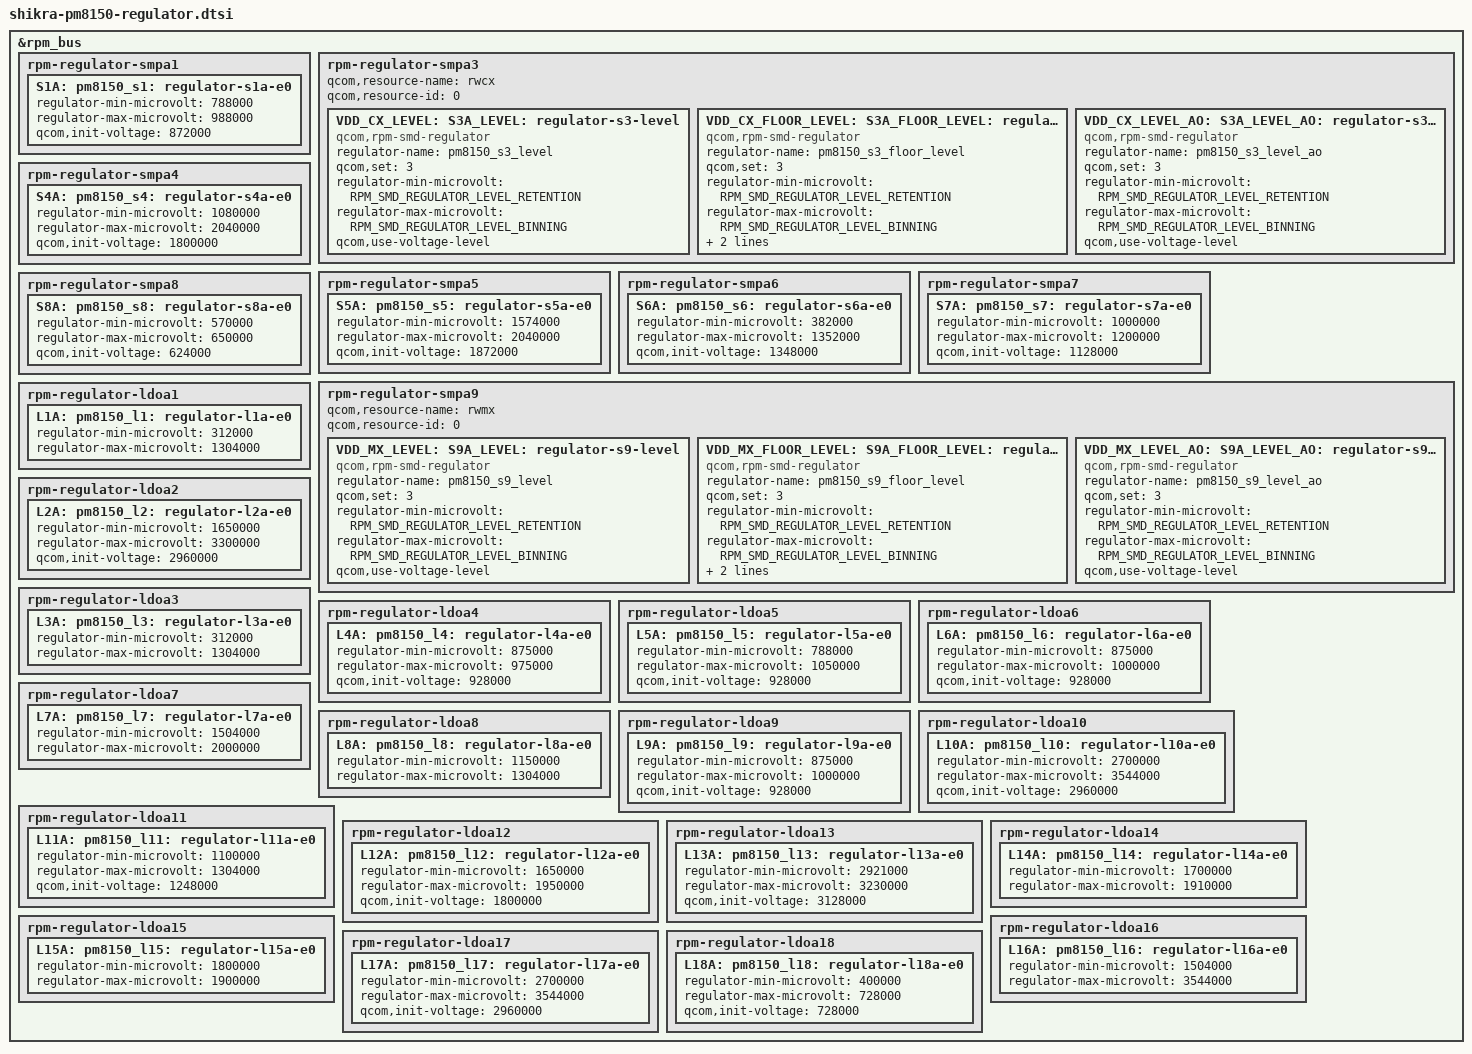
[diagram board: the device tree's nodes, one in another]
// SPDX-License-Identifier: BSD-3-Clause
/*
 * Copyright (c) Qualcomm Technologies, Inc. and/or its subsidiaries.
 */

#include <dt-bindings/regulator/qcom,rpm-smd-regulator.h>
#include "pm8150-rpm-regulator.dtsi"

&rpm_bus {
	rpm-regulator-smpa1 {
		status = "okay";
		S1A: pm8150_s1: regulator-s1a-e0 {
			regulator-min-microvolt = <788000>;
			regulator-max-microvolt = <988000>;
			qcom,init-voltage = <872000>;
			status = "okay";
		};
	};

	rpm-regulator-smpa3 {
		status = "okay";
		qcom,resource-name = "rwcx";
		qcom,resource-id = <0>;

		VDD_CX_LEVEL:
		S3A_LEVEL: pm8150_s3_level: regulator-s3-level {
			compatible = "qcom,rpm-smd-regulator";
			regulator-name = "pm8150_s3_level";
			qcom,set = <3>;
			regulator-min-microvolt =
			<RPM_SMD_REGULATOR_LEVEL_RETENTION>;
			regulator-max-microvolt =
			<RPM_SMD_REGULATOR_LEVEL_BINNING>;
			qcom,use-voltage-level;
		};

		VDD_CX_FLOOR_LEVEL:
		S3A_FLOOR_LEVEL:
		pm8150_s3_floor_level: regulator-s3-floor-level {
			compatible = "qcom,rpm-smd-regulator";
			regulator-name = "pm8150_s3_floor_level";
			qcom,set = <3>;
			regulator-min-microvolt =
			<RPM_SMD_REGULATOR_LEVEL_RETENTION>;
			regulator-max-microvolt =
			<RPM_SMD_REGULATOR_LEVEL_BINNING>;
			qcom,use-voltage-floor-level;
			qcom,always-send-voltage;
		};

		VDD_CX_LEVEL_AO:
		S3A_LEVEL_AO: pm8150_s3_level_ao: regulator-s3-level-ao {
			compatible = "qcom,rpm-smd-regulator";
			regulator-name = "pm8150_s3_level_ao";
			qcom,set = <3>;
			regulator-min-microvolt =
			<RPM_SMD_REGULATOR_LEVEL_RETENTION>;
			regulator-max-microvolt =
			<RPM_SMD_REGULATOR_LEVEL_BINNING>;
			qcom,use-voltage-level;
		};
	};

	rpm-regulator-smpa4 {
		status = "okay";
		S4A: pm8150_s4: regulator-s4a-e0 {
			regulator-min-microvolt = <1080000>;
			regulator-max-microvolt = <2040000>;
			qcom,init-voltage = <1800000>;
			status = "okay";
		};
	};

	rpm-regulator-smpa5 {
		status = "okay";
		S5A: pm8150_s5: regulator-s5a-e0 {
			regulator-min-microvolt = <1574000>;
			regulator-max-microvolt = <2040000>;
			qcom,init-voltage = <1872000>;
			status = "okay";
		};
	};

	rpm-regulator-smpa6 {
		status = "okay";
		S6A: pm8150_s6: regulator-s6a-e0 {
			regulator-min-microvolt = <382000>;
			regulator-max-microvolt = <1352000>;
			qcom,init-voltage = <1348000>;
			status = "okay";
		};
	};

	rpm-regulator-smpa7 {
		status = "okay";
		S7A: pm8150_s7: regulator-s7a-e0 {
			regulator-min-microvolt = <1000000>;
			regulator-max-microvolt = <1200000>;
			qcom,init-voltage = <1128000>;
			status = "okay";
		};
	};

	rpm-regulator-smpa8 {
		status = "okay";
		S8A: pm8150_s8: regulator-s8a-e0 {
			regulator-min-microvolt = <570000>;
			regulator-max-microvolt = <650000>;
			qcom,init-voltage = <624000>;
			status = "okay";
		};
	};

	/* PM8150 S9A - VDD_MX supply */
	rpm-regulator-smpa9 {
		status = "okay";
		qcom,resource-name = "rwmx";
		qcom,resource-id = <0>;

		VDD_MX_LEVEL:
		S9A_LEVEL: pm8150_s9_level: regulator-s9-level {
			compatible = "qcom,rpm-smd-regulator";
			regulator-name = "pm8150_s9_level";
			qcom,set = <3>;
			regulator-min-microvolt =
			<RPM_SMD_REGULATOR_LEVEL_RETENTION>;
			regulator-max-microvolt =
			<RPM_SMD_REGULATOR_LEVEL_BINNING>;
			qcom,use-voltage-level;
		};

		VDD_MX_FLOOR_LEVEL:
		S9A_FLOOR_LEVEL:
		pm8150_s9_floor_level: regulator-s9-floor-level {
			compatible = "qcom,rpm-smd-regulator";
			regulator-name = "pm8150_s9_floor_level";
			qcom,set = <3>;
			regulator-min-microvolt =
			<RPM_SMD_REGULATOR_LEVEL_RETENTION>;
			regulator-max-microvolt =
			<RPM_SMD_REGULATOR_LEVEL_BINNING>;
			qcom,use-voltage-floor-level;
			qcom,always-send-voltage;
		};

		VDD_MX_LEVEL_AO:
		S9A_LEVEL_AO: pm8150_s9_level_ao: regulator-s9-level-ao {
			compatible = "qcom,rpm-smd-regulator";
			regulator-name = "pm8150_s9_level_ao";
			qcom,set = <3>;
			regulator-min-microvolt =
			<RPM_SMD_REGULATOR_LEVEL_RETENTION>;
			regulator-max-microvolt =
			<RPM_SMD_REGULATOR_LEVEL_BINNING>;
			qcom,use-voltage-level;
		};
	};

	rpm-regulator-ldoa1 {
		status = "okay";
		L1A: pm8150_l1: regulator-l1a-e0 {
			regulator-min-microvolt = <312000>;
			regulator-max-microvolt = <1304000>;
			status = "okay";
		};
	};

	rpm-regulator-ldoa2 {
		status = "okay";
		L2A: pm8150_l2: regulator-l2a-e0 {
			regulator-min-microvolt = <1650000>;
			regulator-max-microvolt = <3300000>;
			qcom,init-voltage = <2960000>;
			status = "okay";
		};
	};

	rpm-regulator-ldoa3 {
		status = "okay";
		L3A: pm8150_l3: regulator-l3a-e0 {
			regulator-min-microvolt = <312000>;
			regulator-max-microvolt = <1304000>;
			status = "okay";
		};
	};

	rpm-regulator-ldoa4 {
		status = "okay";
		L4A: pm8150_l4: regulator-l4a-e0 {
			regulator-min-microvolt = <875000>;
			regulator-max-microvolt = <975000>;
			qcom,init-voltage = <928000>;
			status = "okay";
		};
	};

	rpm-regulator-ldoa5 {
		status = "okay";
		L5A: pm8150_l5: regulator-l5a-e0 {
			regulator-min-microvolt = <788000>;
			regulator-max-microvolt = <1050000>;
			qcom,init-voltage = <928000>;
			status = "okay";
		};
	};

	rpm-regulator-ldoa6 {
		status = "okay";
		L6A: pm8150_l6: regulator-l6a-e0 {
			regulator-min-microvolt = <875000>;
			regulator-max-microvolt = <1000000>;
			qcom,init-voltage = <928000>;
			status = "okay";
		};
	};

	rpm-regulator-ldoa7 {
		status = "okay";
		L7A: pm8150_l7: regulator-l7a-e0 {
			regulator-min-microvolt = <1504000>;
			regulator-max-microvolt = <2000000>;
			status = "okay";
		};
	};

	rpm-regulator-ldoa8 {
		status = "okay";
		L8A: pm8150_l8: regulator-l8a-e0 {
			regulator-min-microvolt = <1150000>;
			regulator-max-microvolt = <1304000>;
			status = "okay";
		};
	};

	rpm-regulator-ldoa9 {
		status = "okay";
		L9A: pm8150_l9: regulator-l9a-e0 {
			regulator-min-microvolt = <875000>;
			regulator-max-microvolt = <1000000>;
			qcom,init-voltage = <928000>;
			status = "okay";
		};
	};

	rpm-regulator-ldoa10 {
		status = "okay";
		L10A: pm8150_l10: regulator-l10a-e0 {
			regulator-min-microvolt = <2700000>;
			regulator-max-microvolt = <3544000>;
			qcom,init-voltage = <2960000>;
			status = "okay";
		};
	};

	rpm-regulator-ldoa11 {
		status = "okay";
		L11A: pm8150_l11: regulator-l11a-e0 {
			regulator-min-microvolt = <1100000>;
			regulator-max-microvolt = <1304000>;
			qcom,init-voltage = <1248000>;
			status = "okay";
		};
	};

	rpm-regulator-ldoa12 {
		status = "okay";
		L12A: pm8150_l12: regulator-l12a-e0 {
			regulator-min-microvolt = <1650000>;
			regulator-max-microvolt = <1950000>;
			qcom,init-voltage = <1800000>;
			status = "okay";
		};
	};

	rpm-regulator-ldoa13 {
		status = "okay";
		L13A: pm8150_l13: regulator-l13a-e0 {
			regulator-min-microvolt = <2921000>;
			regulator-max-microvolt = <3230000>;
			qcom,init-voltage = <3128000>;
			status = "okay";
		};
	};

	rpm-regulator-ldoa14 {
		status = "okay";
		L14A: pm8150_l14: regulator-l14a-e0 {
			regulator-min-microvolt = <1700000>;
			regulator-max-microvolt = <1910000>;
			status = "okay";
		};
	};

	rpm-regulator-ldoa15 {
		status = "okay";
		L15A: pm8150_l15: regulator-l15a-e0 {
			regulator-min-microvolt = <1800000>;
			regulator-max-microvolt = <1900000>;
			status = "okay";
		};
	};

	rpm-regulator-ldoa16 {
		status = "okay";
		L16A: pm8150_l16: regulator-l16a-e0 {
			regulator-min-microvolt = <1504000>;
			regulator-max-microvolt = <3544000>;
			status = "okay";
		};
	};

	rpm-regulator-ldoa17 {
		status = "okay";
		L17A: pm8150_l17: regulator-l17a-e0 {
			regulator-min-microvolt = <2700000>;
			regulator-max-microvolt = <3544000>;
			qcom,init-voltage = <2960000>;
			status = "okay";
		};
	};

	rpm-regulator-ldoa18 {
		status = "okay";
		L18A: pm8150_l18: regulator-l18a-e0 {
			regulator-min-microvolt = <400000>;
			regulator-max-microvolt = <728000>;
			qcom,init-voltage = <728000>;
			status = "okay";
		};
	};
};
